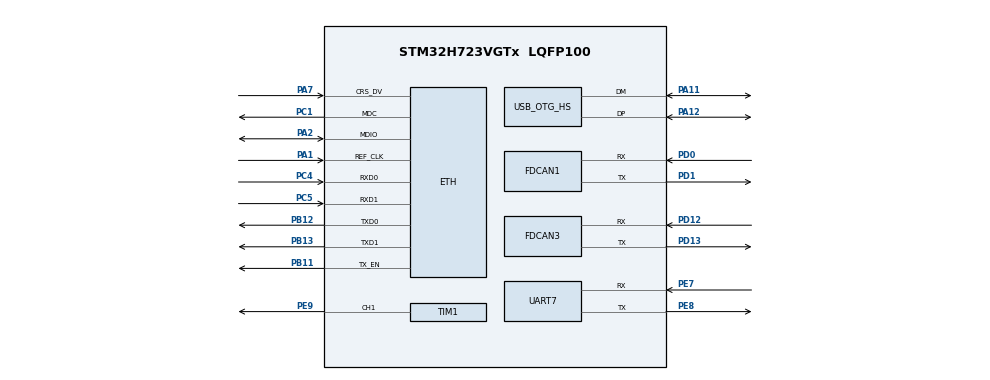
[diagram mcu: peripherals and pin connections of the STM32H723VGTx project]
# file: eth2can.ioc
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CORTEX_M7.AccessPermission_S-Cortex_Memory_Protection_Unit_Region1_Settings_S=MPU_REGION_FULL_ACCESS
CORTEX_M7.AccessPermission_S-Cortex_Memory_Protection_Unit_Region2_Settings_S=MPU_REGION_FULL_ACCESS
CORTEX_M7.BaseAddress_S-Cortex_Memory_Protection_Unit_Region1_Settings_S=0x30000000
CORTEX_M7.BaseAddress_S-Cortex_Memory_Protection_Unit_Region2_Settings_S=0x30000000
CORTEX_M7.CPU_DCache=Enabled
CORTEX_M7.CPU_ICache=Enabled
CORTEX_M7.DisableExec_S-Cortex_Memory_Protection_Unit_Region1_Settings_S=MPU_INSTRUCTION_ACCESS_DISABLE
CORTEX_M7.DisableExec_S-Cortex_Memory_Protection_Unit_Region2_Settings_S=MPU_INSTRUCTION_ACCESS_DISABLE
CORTEX_M7.Enable_S-Cortex_Memory_Protection_Unit_Region1_Settings_S=MPU_REGION_ENABLE
CORTEX_M7.Enable_S-Cortex_Memory_Protection_Unit_Region2_Settings_S=MPU_REGION_ENABLE
CORTEX_M7.IsBufferable_S-Cortex_Memory_Protection_Unit_Region2_Settings_S=MPU_ACCESS_BUFFERABLE
CORTEX_M7.IsShareable_S-Cortex_Memory_Protection_Unit_Region2_Settings_S=MPU_ACCESS_SHAREABLE
CORTEX_M7.Size_S-Cortex_Memory_Protection_Unit_Region1_Settings_S=MPU_REGION_SIZE_32KB
CORTEX_M7.Size_S-Cortex_Memory_Protection_Unit_Region2_Settings_S=MPU_REGION_SIZE_512B
CORTEX_M7.TypeExtField_S-Cortex_Memory_Protection_Unit_Region1_Settings_S=MPU_TEX_LEVEL1
CORTEX_M7.default_mode_Activation=1
Dma.Request0=TIM1_CH1
Dma.TIM1_CH1.0.Direction=DMA_MEMORY_TO_PERIPH
Dma.TIM1_CH1.0.EventEnable=DISABLE
Dma.TIM1_CH1.0.FIFOMode=DMA_FIFOMODE_DISABLE
Dma.TIM1_CH1.0.Instance=DMA1_Stream0
Dma.TIM1_CH1.0.MemDataAlignment=DMA_MDATAALIGN_HALFWORD
Dma.TIM1_CH1.0.MemInc=DMA_MINC_ENABLE
Dma.TIM1_CH1.0.Mode=DMA_CIRCULAR
Dma.TIM1_CH1.0.PeriphDataAlignment=DMA_PDATAALIGN_HALFWORD
Dma.TIM1_CH1.0.PeriphInc=DMA_PINC_DISABLE
Dma.TIM1_CH1.0.Polarity=HAL_DMAMUX_REQ_GEN_RISING
Dma.TIM1_CH1.0.Priority=DMA_PRIORITY_VERY_HIGH
Dma.TIM1_CH1.0.RequestNumber=1
Dma.TIM1_CH1.0.SignalID=NONE
Dma.TIM1_CH1.0.SyncEnable=DISABLE
Dma.TIM1_CH1.0.SyncPolarity=HAL_DMAMUX_SYNC_NO_EVENT
Dma.TIM1_CH1.0.SyncRequestNumber=1
Dma.TIM1_CH1.0.SyncSignalID=NONE
ETH.MediaInterface=HAL_ETH_RMII_MODE
FDCAN1.AutoRetransmission=DISABLE
FDCAN1.CalculateBaudRateNominal=1000000
FDCAN1.CalculateTimeBitNominal=1000
FDCAN1.CalculateTimeQuantumNominal=25.0
FDCAN1.ClockCalibrationCCU=DISABLE
FDCAN1.DataPrescaler=2
FDCAN1.DataSyncJumpWidth=10
FDCAN1.DataTimeSeg1=9
FDCAN1.DataTimeSeg2=10
FDCAN1.FrameFormat=FDCAN_FRAME_FD_BRS
FDCAN1.NominalPrescaler=2
FDCAN1.NominalSyncJumpWidth=10
FDCAN1.NominalTimeSeg1=29
FDCAN1.NominalTimeSeg2=10
FDCAN1.RxBuffersNbr=0
FDCAN1.RxFifo0ElmtSize=FDCAN_DATA_BYTES_64
FDCAN1.RxFifo0ElmtsNbr=16
FDCAN1.RxFifo1ElmtsNbr=0
FDCAN1.TxBuffersNbr=0
FDCAN1.TxElmtSize=FDCAN_DATA_BYTES_64
FDCAN1.TxEventsNbr=0
FDCAN1.TxFifoQueueElmtsNbr=8
FDCAN3.AutoRetransmission=DISABLE
FDCAN3.CalculateBaudRateNominal=1000000
FDCAN3.CalculateTimeBitNominal=1000
FDCAN3.CalculateTimeQuantumNominal=25.0
FDCAN3.DataPrescaler=2
FDCAN3.DataSyncJumpWidth=10
FDCAN3.DataTimeSeg1=9
FDCAN3.DataTimeSeg2=10
FDCAN3.FrameFormat=FDCAN_FRAME_FD_BRS
FDCAN3.MessageRAMOffset=432
FDCAN3.NominalPrescaler=2
FDCAN3.NominalSyncJumpWidth=10
FDCAN3.NominalTimeSeg1=29
FDCAN3.NominalTimeSeg2=10
FDCAN3.RxFifo0ElmtSize=FDCAN_DATA_BYTES_64
FDCAN3.RxFifo0ElmtsNbr=16
FDCAN3.TxElmtSize=FDCAN_DATA_BYTES_64
FDCAN3.TxFifoQueueElmtsNbr=8
FREERTOS.Tasks01=defaultTask,19,6000,StartDefaultTask,As weak,NULL,Dynamic,NULL,NULL
FREERTOS.Timers01=Receivetimer,ReceiveCallback,osTimerPeriodic,As weak,NULL,Dynamic,NULL
FREERTOS.configCHECK_FOR_STACK_OVERFLOW=1
FREERTOS.configMAX_TASK_NAME_LEN=30
FREERTOS.configMINIMAL_STACK_SIZE=512
FREERTOS.configTOTAL_HEAP_SIZE=100000
FREERTOS.configUSE_NEWLIB_REENTRANT=1
LWIP.BSP.number=1
LWIP.DEFAULT_THREAD_STACKSIZE=2048
LWIP.IP_ADDRESS=192.168.010.103
LWIP.IP_DEBUG=LWIP_DBG_OFF
LWIP.IP_REASS_DEBUG=LWIP_DBG_OFF
LWIP.LWIP_DBG_MIN_LEVEL=LWIP_DBG_LEVEL_ALL
LWIP.LWIP_DBG_TYPES_ON=LWIP_DBG_OFF
LWIP.LWIP_DHCP=0
LWIP.LWIP_IGMP=1
LWIP.LWIP_MULTICAST_TX_OPTIONS=1
LWIP.LWIP_RAM_HEAP_POINTER=0x30000200
LWIP.LWIP_TCP=0
LWIP.MEMP_DEBUG=LWIP_DBG_OFF
LWIP.MEMP_NUM_UDP_PCB=15
LWIP.MEM_DEBUG=LWIP_DBG_OFF
LWIP.MEM_SIZE=30000
LWIP.NETMASK_ADDRESS=255.255.000.000
LWIP.PBUF_POOL_SIZE=20
LWIP.RAW_DEBUG=LWIP_DBG_OFF
LWIP.SYS_DEBUG=LWIP_DBG_OFF
LWIP.TCPIP_THREAD_PRIO=20
LWIP.TCPIP_THREAD_STACKSIZE=10000
LWIP.TCP_MSS=1460
LWIP.TCP_SND_BUF=5840
LWIP.TCP_SND_QUEUELEN=16
LWIP.Version=v2.1.2_Cube
LWIP0.BSP.STBoard=false
LWIP0.BSP.api=BSP_COMPONENT_DRIVER
LWIP0.BSP.component=LAN8742
LWIP0.BSP.instance=LAN8742
LWIP0.BSP.name=Driver_PHY
LWIP0.BSP.semaphore=S_LAN8742
LWIP0.BSP.solution=LAN8742
Mcu.Family=STM32H7
Mcu.Name=STM32H723VGTx
Mcu.Package=LQFP100
NVIC.DMA1_Stream0_IRQn=true\:5\:0\:false\:false\:true\:true\:false\:true\:true
NVIC.ETH_IRQn=true\:5\:0\:false\:false\:true\:true\:true\:true\:false
NVIC.FDCAN1_IT0_IRQn=true\:5\:0\:false\:false\:true\:true\:true\:true\:true
NVIC.FDCAN1_IT1_IRQn=true\:5\:0\:false\:false\:true\:true\:true\:true\:true
NVIC.FDCAN3_IT0_IRQn=true\:5\:0\:false\:false\:true\:true\:true\:true\:true
NVIC.FDCAN3_IT1_IRQn=true\:5\:0\:false\:false\:true\:true\:true\:true\:true
NVIC.OTG_HS_IRQn=true\:5\:0\:false\:false\:true\:true\:false\:true\:true
NVIC.PriorityGroup=NVIC_PRIORITYGROUP_4
NVIC.TIM6_DAC_IRQn=true\:15\:0\:false\:false\:true\:false\:false\:true\:true
NVIC.TimeBase=TIM6_DAC_IRQn
NVIC.TimeBaseIP=TIM6
PA1.GPIO_Speed=GPIO_SPEED_FREQ_VERY_HIGH
PA1.Mode=RMII
PA1.Signal=ETH_REF_CLK
PA11.Mode=Device_Only_FS
PA11.Signal=USB_OTG_HS_DM
PA12.Mode=Device_Only_FS
PA12.Signal=USB_OTG_HS_DP
PA2.GPIO_Speed=GPIO_SPEED_FREQ_VERY_HIGH
PA2.Mode=RMII
PA2.Signal=ETH_MDIO
PA7.GPIO_Speed=GPIO_SPEED_FREQ_VERY_HIGH
PA7.Mode=RMII
PA7.Signal=ETH_CRS_DV
PB11.GPIO_Speed=GPIO_SPEED_FREQ_VERY_HIGH
PB11.Mode=RMII
PB11.Signal=ETH_TX_EN
PB12.GPIO_Speed=GPIO_SPEED_FREQ_VERY_HIGH
PB12.Mode=RMII
PB12.Signal=ETH_TXD0
PB13.GPIO_Speed=GPIO_SPEED_FREQ_VERY_HIGH
PB13.Mode=RMII
PB13.Signal=ETH_TXD1
PC1.GPIO_Speed=GPIO_SPEED_FREQ_VERY_HIGH
PC1.Mode=RMII
PC1.Signal=ETH_MDC
PC4.GPIO_Speed=GPIO_SPEED_FREQ_VERY_HIGH
PC4.Mode=RMII
PC4.Signal=ETH_RXD0
PC5.GPIO_Speed=GPIO_SPEED_FREQ_VERY_HIGH
PC5.Mode=RMII
PC5.Signal=ETH_RXD1
PD0.Mode=FDCAN_Activate
PD0.Signal=FDCAN1_RX
PD1.Mode=FDCAN_Activate
PD1.Signal=FDCAN1_TX
PD12.Mode=FDCAN_Activate
PD12.Signal=FDCAN3_RX
PD13.Mode=FDCAN_Activate
PD13.Signal=FDCAN3_TX
PE7.Mode=Asynchronous
PE7.Signal=UART7_RX
PE8.Mode=Asynchronous
PE8.Signal=UART7_TX
PE9.Signal=S_TIM1_CH1
PH0-OSC_IN.Mode=HSE-External-Oscillator
PH0-OSC_IN.Signal=RCC_OSC_IN
PH1-OSC_OUT.Mode=HSE-External-Oscillator
PH1-OSC_OUT.Signal=RCC_OSC_OUT
ProjectManager.HeapSize=0x200
ProjectManager.StackSize=0x400
ProjectManager.TargetToolchain=CMake
RCC.ADCFreq_Value=160000000
RCC.APB1Freq_Value=137500000
RCC.APB2Freq_Value=137500000
RCC.APB3Freq_Value=137500000
RCC.APB4Freq_Value=137500000
RCC.CortexFreq_Value=550000000
RCC.D1PPRE=RCC_APB3_DIV2
RCC.D2PPRE1=RCC_APB1_DIV2
RCC.D2PPRE2=RCC_APB2_DIV2
RCC.D3PPRE=RCC_APB4_DIV2
RCC.DIVM1=8
RCC.DIVM2=4
RCC.DIVN1=275
RCC.DIVN2=80
RCC.DIVN3=130
RCC.DIVP1=1
RCC.DIVQ2=4
RCC.EnbaleCSS=true
RCC.FDCANCLockSelection=RCC_FDCANCLKSOURCE_PLL2
RCC.HCLKFreq_Value=275000000
RCC.HPRE=RCC_HCLK_DIV2
RCC.HSE_VALUE=16000000
RCC.PLLFRACN=0
RCC.PLLSourceVirtual=RCC_PLLSOURCE_HSE
RCC.SYSCLKFreq_VALUE=550000000
RCC.SYSCLKSource=RCC_SYSCLKSOURCE_PLLCLK
RCC.USBCLockSelection=RCC_USBCLKSOURCE_HSI48
RCC.USBFreq_Value=48000000
SH.S_TIM1_CH1.0=TIM1_CH1,PWM Generation1 CH1
TIM1.Channel-PWM\ Generation1\ CH1=TIM_CHANNEL_1
TIM1.OCFastMode_PWM-PWM\ Generation1\ CH1=TIM_OCFAST_ENABLE
TIM1.Period=85
TIM1.Prescaler=16
USB_DEVICE.CLASS_NAME_HS=CDC
USB_DEVICE.PRODUCT_STRING_CDC_HS=Ethernet to CANFD Debug
USB_DEVICE.VirtualMode=Cdc
USB_DEVICE.VirtualModeHS=Cdc_HS
USB_OTG_HS.VirtualMode-Device_Only_FS=Device_Only_FS
VP_FREERTOS_VS_CMSIS_V2.Mode=CMSIS_V2
VP_LWIP_VS_Enabled.Mode=Enabled
VP_MEMORYMAP_VS_MEMORYMAP.Mode=CurAppReg
VP_SYS_VS_tim6.Mode=TIM6
VP_USB_DEVICE_VS_USB_DEVICE_CDC_HS.Mode=CDC_HS
board=custom

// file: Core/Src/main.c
/* USER CODE BEGIN Header */
/**
  ******************************************************************************
  * @file           : main.c
  * @brief          : Main program body
  ******************************************************************************
  * @attention
  *
  * Copyright (c) 2025 STMicroelectronics.
  * All rights reserved.
  *
  * This software is licensed under terms that can be found in the LICENSE file
  * in the root directory of this software component.
  * If no LICENSE file comes with this software, it is provided AS-IS.
  *
  ******************************************************************************
  */
/* USER CODE END Header */
#include "main.h"
#include "cmsis_os.h"
#include "dma.h"
#include "fdcan.h"
#include "lwip.h"
#include "memorymap.h"
#include "tim.h"
#include "usart.h"
#include "usb_device.h"
#include "gpio.h"

/* USER CODE BEGIN PTD */
int _write(int file, char *ptr, int len)
{
  HAL_UART_Transmit(&huart7,(uint8_t *)ptr,len,10);
  return len;
}
/* USER CODE END PTD */

void SystemClock_Config(void);
void PeriphCommonClock_Config(void);
static void MPU_Config(void);
void MX_FREERTOS_Init(void);

int main(void)
{

  /* MPU Configuration--------------------------------------------------------*/
  MPU_Config();

  /* Enable the CPU Cache */

  /* Enable I-Cache---------------------------------------------------------*/
  SCB_EnableICache();

  /* Enable D-Cache---------------------------------------------------------*/
  SCB_EnableDCache();

  /* MCU Configuration--------------------------------------------------------*/

  /* Reset of all peripherals, Initializes the Flash interface and the Systick. */
  HAL_Init();

  /* Configure the system clock */
  SystemClock_Config();

  /* Configure the peripherals common clocks */
  PeriphCommonClock_Config();

  /* Initialize all configured peripherals */
  MX_GPIO_Init();
  MX_DMA_Init();
  MX_TIM1_Init();
  MX_FDCAN1_Init();
  MX_FDCAN3_Init();
  MX_UART7_Init();

  /* Init scheduler */
  osKernelInitialize();

  /* Call init function for freertos objects (in cmsis_os2.c) */
  MX_FREERTOS_Init();

  /* Start scheduler */
  osKernelStart();

  /* We should never get here as control is now taken by the scheduler */

  /* Infinite loop */
  while (1)
  {

  }
}

void SystemClock_Config(void)
{
  RCC_OscInitTypeDef RCC_OscInitStruct = {0};
  RCC_ClkInitTypeDef RCC_ClkInitStruct = {0};

  /** Supply configuration update enable
  */
  HAL_PWREx_ConfigSupply(PWR_LDO_SUPPLY);

  /** Configure the main internal regulator output voltage
  */
  __HAL_PWR_VOLTAGESCALING_CONFIG(PWR_REGULATOR_VOLTAGE_SCALE0);

  while(!__HAL_PWR_GET_FLAG(PWR_FLAG_VOSRDY)) {}

  /** Initializes the RCC Oscillators according to the specified parameters
  * in the RCC_OscInitTypeDef structure.
  */
  RCC_OscInitStruct.OscillatorType = RCC_OSCILLATORTYPE_HSI48|RCC_OSCILLATORTYPE_HSE;
  RCC_OscInitStruct.HSEState = RCC_HSE_ON;
  RCC_OscInitStruct.HSI48State = RCC_HSI48_ON;
  RCC_OscInitStruct.PLL.PLLState = RCC_PLL_ON;
  RCC_OscInitStruct.PLL.PLLSource = RCC_PLLSOURCE_HSE;
  RCC_OscInitStruct.PLL.PLLM = 8;
  RCC_OscInitStruct.PLL.PLLN = 275;
  RCC_OscInitStruct.PLL.PLLP = 1;
  RCC_OscInitStruct.PLL.PLLQ = 2;
  RCC_OscInitStruct.PLL.PLLR = 2;
  RCC_OscInitStruct.PLL.PLLRGE = RCC_PLL1VCIRANGE_1;
  RCC_OscInitStruct.PLL.PLLVCOSEL = RCC_PLL1VCOWIDE;
  RCC_OscInitStruct.PLL.PLLFRACN = 0;
  if (HAL_RCC_OscConfig(&RCC_OscInitStruct) != HAL_OK)
  {
    Error_Handler();
  }

  /** Initializes the CPU, AHB and APB buses clocks
  */
  RCC_ClkInitStruct.ClockType = RCC_CLOCKTYPE_HCLK|RCC_CLOCKTYPE_SYSCLK
                              |RCC_CLOCKTYPE_PCLK1|RCC_CLOCKTYPE_PCLK2
                              |RCC_CLOCKTYPE_D3PCLK1|RCC_CLOCKTYPE_D1PCLK1;
  RCC_ClkInitStruct.SYSCLKSource = RCC_SYSCLKSOURCE_PLLCLK;
  RCC_ClkInitStruct.SYSCLKDivider = RCC_SYSCLK_DIV1;
  RCC_ClkInitStruct.AHBCLKDivider = RCC_HCLK_DIV2;
  RCC_ClkInitStruct.APB3CLKDivider = RCC_APB3_DIV2;
  RCC_ClkInitStruct.APB1CLKDivider = RCC_APB1_DIV2;
  RCC_ClkInitStruct.APB2CLKDivider = RCC_APB2_DIV2;
  RCC_ClkInitStruct.APB4CLKDivider = RCC_APB4_DIV2;

  if (HAL_RCC_ClockConfig(&RCC_ClkInitStruct, FLASH_LATENCY_3) != HAL_OK)
  {
    Error_Handler();
  }

  /** Enables the Clock Security System
  */
  HAL_RCC_EnableCSS();
}

void PeriphCommonClock_Config(void)
{
  RCC_PeriphCLKInitTypeDef PeriphClkInitStruct = {0};

  /** Initializes the peripherals clock
  */
  PeriphClkInitStruct.PeriphClockSelection = RCC_PERIPHCLK_FDCAN;
  PeriphClkInitStruct.PLL2.PLL2M = 4;
  PeriphClkInitStruct.PLL2.PLL2N = 80;
  PeriphClkInitStruct.PLL2.PLL2P = 2;
  PeriphClkInitStruct.PLL2.PLL2Q = 4;
  PeriphClkInitStruct.PLL2.PLL2R = 2;
  PeriphClkInitStruct.PLL2.PLL2RGE = RCC_PLL2VCIRANGE_2;
  PeriphClkInitStruct.PLL2.PLL2VCOSEL = RCC_PLL2VCOWIDE;
  PeriphClkInitStruct.PLL2.PLL2FRACN = 0;
  PeriphClkInitStruct.FdcanClockSelection = RCC_FDCANCLKSOURCE_PLL2;
  if (HAL_RCCEx_PeriphCLKConfig(&PeriphClkInitStruct) != HAL_OK)
  {
    Error_Handler();
  }
}

 /* MPU Configuration */

void MPU_Config(void)
{
  MPU_Region_InitTypeDef MPU_InitStruct = {0};

  /* Disables the MPU */
  HAL_MPU_Disable();

  /** Initializes and configures the Region and the memory to be protected
  */
  MPU_InitStruct.Enable = MPU_REGION_ENABLE;
  MPU_InitStruct.Number = MPU_REGION_NUMBER0;
  MPU_InitStruct.BaseAddress = 0x0;
  MPU_InitStruct.Size = MPU_REGION_SIZE_4GB;
  MPU_InitStruct.SubRegionDisable = 0x87;
  MPU_InitStruct.TypeExtField = MPU_TEX_LEVEL0;
  MPU_InitStruct.AccessPermission = MPU_REGION_NO_ACCESS;
  MPU_InitStruct.DisableExec = MPU_INSTRUCTION_ACCESS_DISABLE;
  MPU_InitStruct.IsShareable = MPU_ACCESS_SHAREABLE;
  MPU_InitStruct.IsCacheable = MPU_ACCESS_NOT_CACHEABLE;
  MPU_InitStruct.IsBufferable = MPU_ACCESS_NOT_BUFFERABLE;

  HAL_MPU_ConfigRegion(&MPU_InitStruct);

  /** Initializes and configures the Region and the memory to be protected
  */
  MPU_InitStruct.Number = MPU_REGION_NUMBER1;
  MPU_InitStruct.BaseAddress = 0x30000000;
  MPU_InitStruct.Size = MPU_REGION_SIZE_32KB;
  MPU_InitStruct.SubRegionDisable = 0x0;
  MPU_InitStruct.TypeExtField = MPU_TEX_LEVEL1;
  MPU_InitStruct.AccessPermission = MPU_REGION_FULL_ACCESS;
  MPU_InitStruct.IsShareable = MPU_ACCESS_NOT_SHAREABLE;

  HAL_MPU_ConfigRegion(&MPU_InitStruct);

  /** Initializes and configures the Region and the memory to be protected
  */
  MPU_InitStruct.Number = MPU_REGION_NUMBER2;
  MPU_InitStruct.Size = MPU_REGION_SIZE_512B;
  MPU_InitStruct.TypeExtField = MPU_TEX_LEVEL0;
  MPU_InitStruct.IsShareable = MPU_ACCESS_SHAREABLE;
  MPU_InitStruct.IsBufferable = MPU_ACCESS_BUFFERABLE;

  HAL_MPU_ConfigRegion(&MPU_InitStruct);
  /* Enables the MPU */
  HAL_MPU_Enable(MPU_PRIVILEGED_DEFAULT);

}

void HAL_TIM_PeriodElapsedCallback(TIM_HandleTypeDef *htim)
{
  if (htim->Instance == TIM6)
  {
    HAL_IncTick();
  }
}

void Error_Handler(void)
{
  __disable_irq();
  while (1)
  {
  }
}

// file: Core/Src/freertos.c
/* USER CODE BEGIN Header */
/**
  ******************************************************************************
  * File Name          : freertos.c
  * Description        : Code for freertos applications
  ******************************************************************************
  * @attention
  *
  * Copyright (c) 2025 STMicroelectronics.
  * All rights reserved.
  *
  * This software is licensed under terms that can be found in the LICENSE file
  * in the root directory of this software component.
  * If no LICENSE file comes with this software, it is provided AS-IS.
  *
  ******************************************************************************
  */
/* USER CODE END Header */

#include "FreeRTOS.h"
#include "task.h"
#include "main.h"
#include "cmsis_os.h"

/* Definitions for defaultTask */
osThreadId_t defaultTaskHandle;
const osThreadAttr_t defaultTask_attributes = {
  .name = "defaultTask",
  .stack_size = 6000 * 4,
  .priority = (osPriority_t) osPriorityBelowNormal3,
};
/* Definitions for Receivetimer */
osTimerId_t ReceivetimerHandle;
const osTimerAttr_t Receivetimer_attributes = {
  .name = "Receivetimer"
};

void StartDefaultTask(void *argument);
void ReceiveCallback(void *argument);

extern void MX_LWIP_Init(void);
extern void MX_USB_DEVICE_Init(void);
void MX_FREERTOS_Init(void); /* (MISRA C 2004 rule 8.1) */

/* Hook prototypes */
void vApplicationStackOverflowHook(xTaskHandle xTask, signed char *pcTaskName);

/* USER CODE BEGIN 4 */
void vApplicationStackOverflowHook(xTaskHandle xTask, signed char *pcTaskName)
{
   /* Run time stack overflow checking is performed if
   configCHECK_FOR_STACK_OVERFLOW is defined to 1 or 2. This hook function is
   called if a stack overflow is detected. */
}
/* USER CODE END 4 */

void MX_FREERTOS_Init(void) {

  /* Create the timer(s) */
  /* creation of Receivetimer */
  ReceivetimerHandle = osTimerNew(ReceiveCallback, osTimerPeriodic, NULL, &Receivetimer_attributes);

  /* Create the thread(s) */
  /* creation of defaultTask */
  defaultTaskHandle = osThreadNew(StartDefaultTask, NULL, &defaultTask_attributes);

}

__weak void StartDefaultTask(void *argument)
{
  /* init code for LWIP */
  MX_LWIP_Init();

  /* init code for USB_DEVICE */
  MX_USB_DEVICE_Init();
  for(;;)
  {
    osDelay(1);
  }
}

/* ReceiveCallback function */
__weak void ReceiveCallback(void *argument)
{
}
